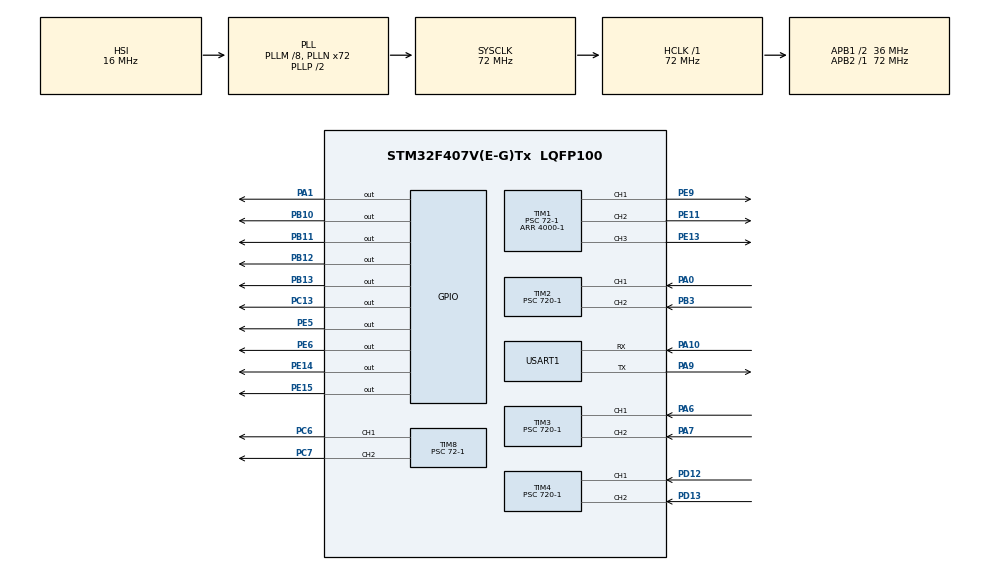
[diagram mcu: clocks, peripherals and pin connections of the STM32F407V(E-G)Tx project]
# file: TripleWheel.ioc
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Mcu.Family=STM32F4
Mcu.Name=STM32F407V(E-G)Tx
Mcu.Package=LQFP100
NVIC.PriorityGroup=NVIC_PRIORITYGROUP_4
NVIC.TIM5_IRQn=true\:0\:0\:false\:false\:true\:true\:true\:true
NVIC.USART1_IRQn=true\:0\:0\:false\:false\:true\:true\:true\:true
PA0-WKUP.Signal=S_TIM2_CH1_ETR
PA1.Signal=GPIO_Output
PA10.Mode=Asynchronous
PA10.Signal=USART1_RX
PA13.Mode=Serial_Wire
PA13.Signal=SYS_JTMS-SWDIO
PA14.Mode=Serial_Wire
PA14.Signal=SYS_JTCK-SWCLK
PA6.Signal=S_TIM3_CH1
PA7.Signal=S_TIM3_CH2
PA9.Mode=Asynchronous
PA9.Signal=USART1_TX
PB10.Signal=GPIO_Output
PB11.Signal=GPIO_Output
PB12.Signal=GPIO_Output
PB13.Signal=GPIO_Output
PB3.Signal=S_TIM2_CH2
PC13-ANTI_TAMP.Signal=GPIO_Output
PC14-OSC32_IN.Mode=LSE-External-Oscillator
PC14-OSC32_IN.Signal=RCC_OSC32_IN
PC15-OSC32_OUT.Mode=LSE-External-Oscillator
PC15-OSC32_OUT.Signal=RCC_OSC32_OUT
PC6.Signal=S_TIM8_CH1
PC7.Signal=S_TIM8_CH2
PD12.Signal=S_TIM4_CH1
PD13.Signal=S_TIM4_CH2
PE11.Signal=S_TIM1_CH2
PE13.Signal=S_TIM1_CH3
PE14.Signal=GPIO_Output
PE15.Signal=GPIO_Output
PE5.Signal=GPIO_Output
PE6.Signal=GPIO_Output
PE9.Signal=S_TIM1_CH1
PH0-OSC_IN.Mode=HSE-External-Oscillator
PH0-OSC_IN.Signal=RCC_OSC_IN
PH1-OSC_OUT.Mode=HSE-External-Oscillator
PH1-OSC_OUT.Signal=RCC_OSC_OUT
ProjectManager.HeapSize=0x200
ProjectManager.StackSize=0x400
ProjectManager.TargetToolchain=CMake
RCC.48MHZClocksFreq_Value=36000000
RCC.AHBFreq_Value=72000000
RCC.APB1CLKDivider=RCC_HCLK_DIV2
RCC.APB1Freq_Value=36000000
RCC.APB1TimFreq_Value=72000000
RCC.APB2Freq_Value=72000000
RCC.APB2TimFreq_Value=72000000
RCC.CortexFreq_Value=72000000
RCC.HCLKFreq_Value=72000000
RCC.HSE_VALUE=25000000
RCC.HSI_VALUE=16000000
RCC.PLLM=8
RCC.PLLN=72
RCC.SYSCLKFreq_VALUE=72000000
RCC.SYSCLKSource=RCC_SYSCLKSOURCE_PLLCLK
RCC.VCOOutputFreq_Value=144000000
SH.S_TIM1_CH1.0=TIM1_CH1,PWM Generation1 CH1
SH.S_TIM1_CH2.0=TIM1_CH2,PWM Generation2 CH2
SH.S_TIM1_CH3.0=TIM1_CH3,PWM Generation3 CH3
SH.S_TIM2_CH1_ETR.0=TIM2_CH1,Encoder_Interface
SH.S_TIM2_CH2.0=TIM2_CH2,Encoder_Interface
SH.S_TIM3_CH1.0=TIM3_CH1,Encoder_Interface
SH.S_TIM3_CH2.0=TIM3_CH2,Encoder_Interface
SH.S_TIM4_CH1.0=TIM4_CH1,Encoder_Interface
SH.S_TIM4_CH2.0=TIM4_CH2,Encoder_Interface
SH.S_TIM8_CH1.0=TIM8_CH1,PWM Generation1 CH1
SH.S_TIM8_CH2.0=TIM8_CH2,PWM Generation2 CH2
TIM1.Channel-PWM\ Generation1\ CH1=TIM_CHANNEL_1
TIM1.Channel-PWM\ Generation2\ CH2=TIM_CHANNEL_2
TIM1.Channel-PWM\ Generation3\ CH3=TIM_CHANNEL_3
TIM1.Period=4000-1
TIM1.Prescaler=72-1
TIM2.Period=20000
TIM2.Prescaler=720-1
TIM3.Period=20000
TIM3.Prescaler=720-1
TIM4.Period=20000
TIM4.Prescaler=720-1
TIM5.Period=1000-1
TIM5.Prescaler=72-1
TIM8.Channel-PWM\ Generation1\ CH1=TIM_CHANNEL_1
TIM8.Channel-PWM\ Generation2\ CH2=TIM_CHANNEL_2
TIM8.Period=20000-1
TIM8.Prescaler=72-1
TIM8.Pulse-PWM\ Generation1\ CH1=2000
TIM8.Pulse-PWM\ Generation2\ CH2=2000
USART1.VirtualMode=VM_ASYNC
VP_TIM1_VS_ClockSourceINT.Mode=Internal
VP_TIM5_VS_ClockSourceINT.Mode=Internal
board=custom

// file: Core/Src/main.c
/* USER CODE BEGIN Header */
/**
 ******************************************************************************
 * @file           : main.c
 * @brief          : Main program body
 ******************************************************************************
 * @attention
 *
 * Copyright (c) 2024 STMicroelectronics.
 * All rights reserved.
 *
 * This software is licensed under terms that can be found in the LICENSE file
 * in the root directory of this software component.
 * If no LICENSE file comes with this software, it is provided AS-IS.
 *
 ******************************************************************************
 */
/* USER CODE END Header */
#include "main.h"
#include "tim.h"
#include "usart.h"
#include "gpio.h"

/* USER CODE BEGIN Includes */
#include "entrypoint.hh"
/* USER CODE END Includes */

void SystemClock_Config(void);

int main(void)
{

  /* MCU Configuration--------------------------------------------------------*/

  /* Reset of all peripherals, Initializes the Flash interface and the Systick. */
  HAL_Init();

  /* Configure the system clock */
  SystemClock_Config();

  /* Initialize all configured peripherals */
  MX_GPIO_Init();
  MX_TIM1_Init();
  MX_TIM2_Init();
  MX_TIM3_Init();
  MX_TIM4_Init();
  MX_TIM5_Init();
  MX_USART1_UART_Init();
  MX_TIM8_Init();
  /* USER CODE BEGIN 2 */

  entrypoint();

  /* USER CODE END 2 */

  /* Infinite loop */
  while (1) {

  }
}

void SystemClock_Config(void)
{
  RCC_OscInitTypeDef RCC_OscInitStruct = {0};
  RCC_ClkInitTypeDef RCC_ClkInitStruct = {0};

  /** Configure the main internal regulator output voltage
  */
  __HAL_RCC_PWR_CLK_ENABLE();
  __HAL_PWR_VOLTAGESCALING_CONFIG(PWR_REGULATOR_VOLTAGE_SCALE1);

  /** Initializes the RCC Oscillators according to the specified parameters
  * in the RCC_OscInitTypeDef structure.
  */
  RCC_OscInitStruct.OscillatorType = RCC_OSCILLATORTYPE_HSI;
  RCC_OscInitStruct.HSIState = RCC_HSI_ON;
  RCC_OscInitStruct.HSICalibrationValue = RCC_HSICALIBRATION_DEFAULT;
  RCC_OscInitStruct.PLL.PLLState = RCC_PLL_ON;
  RCC_OscInitStruct.PLL.PLLSource = RCC_PLLSOURCE_HSI;
  RCC_OscInitStruct.PLL.PLLM = 8;
  RCC_OscInitStruct.PLL.PLLN = 72;
  RCC_OscInitStruct.PLL.PLLP = RCC_PLLP_DIV2;
  RCC_OscInitStruct.PLL.PLLQ = 4;
  if (HAL_RCC_OscConfig(&RCC_OscInitStruct) != HAL_OK)
  {
    Error_Handler();
  }

  /** Initializes the CPU, AHB and APB buses clocks
  */
  RCC_ClkInitStruct.ClockType = RCC_CLOCKTYPE_HCLK|RCC_CLOCKTYPE_SYSCLK
                              |RCC_CLOCKTYPE_PCLK1|RCC_CLOCKTYPE_PCLK2;
  RCC_ClkInitStruct.SYSCLKSource = RCC_SYSCLKSOURCE_PLLCLK;
  RCC_ClkInitStruct.AHBCLKDivider = RCC_SYSCLK_DIV1;
  RCC_ClkInitStruct.APB1CLKDivider = RCC_HCLK_DIV2;
  RCC_ClkInitStruct.APB2CLKDivider = RCC_HCLK_DIV1;

  if (HAL_RCC_ClockConfig(&RCC_ClkInitStruct, FLASH_LATENCY_2) != HAL_OK)
  {
    Error_Handler();
  }
}

void Error_Handler(void)
{
  __disable_irq();
  while (1) {
  }
}

#ifdef  USE_FULL_ASSERT
/**
  * @brief  Reports the name of the source file and the source line number
  *         where the assert_param error has occurred.
  * @param  file: pointer to the source file name
  * @param  line: assert_param error line source number
  * @retval None
  */
void assert_failed(uint8_t *file, uint32_t line)
{
  /* USER CODE BEGIN 6 */
  /* User can add his own implementation to report the file name and line
     number, ex: printf("Wrong parameters value: file %s on line %d\r\n", file,
     line) */
  /* USER CODE END 6 */
}
#endif /* USE_FULL_ASSERT */
